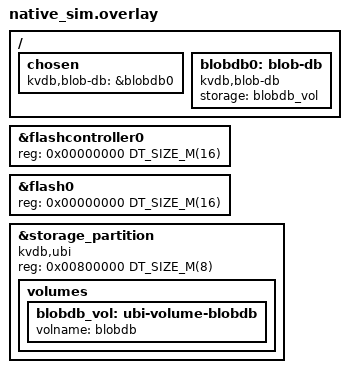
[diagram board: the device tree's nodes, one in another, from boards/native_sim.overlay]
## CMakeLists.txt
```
# Copyright (c) 2026
# SPDX-License-Identifier: Apache-2.0

cmake_minimum_required(VERSION 3.20.0)
find_package(Zephyr REQUIRED HINTS $ENV{ZEPHYR_BASE})
project(blob_db_test)

# The repository is a Zephyr module (see zephyr/module.yml): its top-level
# CMakeLists already adds lib/ and exports include/, and the blob_db library
# is built and linked automatically when CONFIG_BLOB_DB=y. Re-adding lib/
# here would create a duplicate `blob_db` target, so we only add the test.
target_sources(app PRIVATE src/main.c)
# blob_db_maintain(), its work-queue helper and the library lock.
target_sources(app PRIVATE src/maint.c)
# Power cuts during a compaction, injected under the store seam by the flash
# simulator, so they hold on every backend.
target_sources(app PRIVATE src/power_cut.c)
target_sources(app PRIVATE src/torn_append.c)
# Slots a newer build wrote, and what compaction may drop past the log's end.
target_sources(app PRIVATE src/foreign_slot.c)
# The major-5 master: header, record log, rotation, mount's doubt rules.
target_sources(app PRIVATE src/master_log.c)
# Delta slots: values against a model, and power cuts inside delta appends and
# inside compactions that rewrite chains.
target_sources_ifdef(CONFIG_BLOB_DB_DELTA app PRIVATE src/delta.c)
target_sources(app PRIVATE src/slot_index_clock.c)
# The UBI backend's own behaviour: refusing a substrate it cannot read, and the
# application hooks of <app/lib/blob_db_ubi.h>.
target_sources_ifdef(CONFIG_BLOB_DB_BACKEND_UBI app PRIVATE src/ubi.c)
```

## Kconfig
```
# Copyright (c) 2026
# SPDX-License-Identifier: Apache-2.0

mainmenu "blob_db ztest"

menu "Zephyr"
source "Kconfig.zephyr"
endmenu

# The blob_db library's Kconfig (CONFIG_BLOB_DB and friends) is contributed by
# the repository's module Kconfig entry point (zephyr/module.yml -> Kconfig ->
# rsource lib/Kconfig), so it must not be sourced again here.
```

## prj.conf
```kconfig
CONFIG_ZTEST=y
CONFIG_BLOB_DB=y
# blob_db_info_get() / blob_db_bucket_stat(), covered by the inspect cases.
CONFIG_BLOB_DB_INSPECT=y

# The corrupted-slot test bit-flips an already-written byte to simulate
# real-flash bit-rot; sim-flash refuses that by default.
CONFIG_FLASH_SIMULATOR_DOUBLE_WRITES=y

# src/power_cut.c cuts the power through the simulator's write and erase
# callbacks.
CONFIG_FLASH_SIMULATOR_CALLBACKS=y

# Compaction holds two 4 KB scratch buffers nested under a 4 KB bucket
# buffer; bump stack and ztest thread stack to fit.
CONFIG_MAIN_STACK_SIZE=32768
CONFIG_ZTEST_STACK_SIZE=32768

# Flash I/O counters, and the cause counters checked against them by
# test_iostats_causes_account_for_erases. Counting only; no behaviour changes.
CONFIG_BLOB_DB_IOSTATS=y
```

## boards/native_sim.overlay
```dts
/*
 * Match the app's overlay: 16 MB sim-flash with an 8 MB storage_partition
 * at offset 0x800000. Required so blob_db sees ≥ 4 sectors and exercises
 * the multi-bucket layout in tests.
 */

&flashcontroller0 {
	reg = <0x00000000 DT_SIZE_M(16)>;
};

&flash0 {
	reg = <0x00000000 DT_SIZE_M(16)>;
};

&storage_partition {
	/* A UBI device with one volume, which blob_db lives on. Keep
	 * "zephyr,mapped-partition": it is what makes the node a partition on
	 * native_sim.
	 */
	compatible = "kvdb,ubi", "zephyr,mapped-partition";
	reg = <0x00800000 DT_SIZE_M(8)>;

	volumes {
		blobdb_vol: ubi-volume-blobdb {
			volname = "blobdb";
		};
	};
};

/*
 * The blob_db store on the volume above. No "automount": the suite mounts,
 * formats and unmounts the store itself.
 */
/ {
	chosen {
		kvdb,blob-db = &blobdb0;
	};

	blobdb0: blob-db {
		compatible = "kvdb,blob-db";
		storage = <&blobdb_vol>;
	};
};
```

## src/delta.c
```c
/*
 * Copyright (c) 2026
 * SPDX-License-Identifier: Apache-2.0
 *
 * Delta slots (CONFIG_BLOB_DB_DELTA): an update that changes one contiguous
 * part of a value may be stored as the change against an earlier slot of the
 * same id, and every read rebuilds the value.
 *
 * blob_db_delta checks values, not mechanics: a random sequence of edits on a
 * handful of ids sharing buckets, compared after every write with a model and
 * across remounts, long enough for every bucket involved to compact. A few
 * cases then pin the mechanics the random run relies on.
 *
 * blob_db_delta_power cuts the power at every byte (and every erase) of an
 * update that appends a delta on top of a chain, and of one that compacts a
 * bucket holding chains, then checks the value the id reads back is wholly the
 * old one or wholly the new one, and that its neighbours are untouched.
 */

#include <errno.h>
#include <stdbool.h>
#include <stdint.h>
#include <string.h>

#include <zephyr/drivers/flash.h>
#include <zephyr/drivers/flash/flash_simulator.h>
#include <zephyr/storage/flash_map.h>
#include <zephyr/ztest.h>

#include <app/lib/blob_db.h>
#include <app/lib/blob_db_inspect.h>
#if defined(CONFIG_BLOB_DB_IOSTATS)
#include <app/lib/blob_db_iostats.h>
#endif

#define D_PARTITION_ID   PARTITION_ID(storage_partition)
#define D_PARTITION_SIZE DT_REG_SIZE(DT_NODELABEL(storage_partition))
#define MAXV             400   /* largest value the model builds */

/* Deterministic PRNG, so a failure replays. */
static uint32_t rng = 0x2545f491;

static uint32_t rnd(uint32_t n)
{
	rng ^= rng << 13;
	rng ^= rng >> 17;
	rng ^= rng << 5;
	return n ? rng % n : 0;
}

static void fill(uint8_t *p, size_t n)
{
	for (size_t i = 0; i < n; i++) {
		p[i] = (uint8_t)rnd(256);
	}
}

static void expect_value(uint64_t id, const uint8_t *want, size_t len, const char *when)
{
	static uint8_t got[MAXV + 8];
	size_t got_len = 0;

	zassert_ok(blob_db_get(id, got, sizeof(got), &got_len), "%s: get id %llu", when,
		   (unsigned long long)id);
	zassert_equal(got_len, len, "%s: id %llu length %zu, want %zu", when,
		      (unsigned long long)id, got_len, len);
	zassert_mem_equal(got, want, len, "%s: id %llu content", when, (unsigned long long)id);

	size_t sz = 0;

	zassert_ok(blob_db_size(id, &sz));
	zassert_equal(sz, len, "%s: size of id %llu", when, (unsigned long long)id);
}

/* One edit of the kind the recorded traffic makes, or a harder one. */
static void edit(uint8_t *v, size_t *len)
{
	size_t n = *len;
	uint32_t at = rnd((uint32_t)n + 1);
	uint32_t k;

	switch (rnd(8)) {
	case 0: /* overwrite a few bytes (counters, timestamps) */
		k = 1 + rnd(4);
		for (uint32_t i = 0; i < k && at + i < n; i++) {
			v[at + i] ^= (uint8_t)(1 + rnd(255));
		}
		break;
	case 1: /* append an entry (kvhash insert) */
		k = 1 + rnd(24);
		if (n + k <= MAXV) {
			fill(v + n, k);
			n += k;
		}
		break;
	case 2: /* insert in the middle */
		k = 1 + rnd(24);
		if (n + k <= MAXV) {
			memmove(v + at + k, v + at, n - at);
			fill(v + at, k);
			n += k;
		}
		break;
	case 3: /* remove a range */
		k = 1 + rnd(24);
		if (at + k <= n) {
			memmove(v + at, v + at + k, n - at - k);
			n -= k;
		}
		break;
	case 4: /* move a range to the end (a kvhash replace) */
		k = 1 + rnd(24);
		if (at + k <= n) {
			uint8_t tmp[24];

			memcpy(tmp, v + at, k);
			memmove(v + at, v + at + k, n - at - k);
			memcpy(v + n - k, tmp, k);
			v[n - 1] ^= 0x5a;
		}
		break;
	case 5: /* replace everything */
		n = 1 + rnd(MAXV);
		fill(v, n);
		break;
	case 6: /* truncate */
		if (n > 1) {
			n = 1 + rnd((uint32_t)n - 1);
		}
		break;
	default: /* unchanged */
		break;
	}
	*len = n;
}

/* blob_db_delta ----------------------------------------------------------- */

static void delta_before(void *fixture)
{
	ARG_UNUSED(fixture);
	blob_db_unmount();
	zassert_ok(blob_db_mount());
	zassert_ok(blob_db_format());
}

static void delta_after(void *fixture)
{
	ARG_UNUSED(fixture);
	blob_db_unmount();
}

ZTEST_SUITE(blob_db_delta, NULL, NULL, delta_before, delta_after, NULL);

#define N_IDS   12
#define N_STEPS 6000

ZTEST(blob_db_delta, test_random_edits_match_a_model)
{
	static uint8_t val[N_IDS][MAXV];
	static size_t len[N_IDS];
	uint64_t id[N_IDS];
	struct blob_db_inspect_info in;
	uint32_t gen0[N_IDS];

	zassert_ok(blob_db_inspect_info_get(&in));
	for (int i = 0; i < N_IDS; i++) {
		len[i] = 16 + rnd(200);
		fill(val[i], len[i]);
		id[i] = blob_db_alloc_id();
		zassert_ok(blob_db_update(id[i], val[i], len[i]));

		struct blob_db_inspect_bucket bs;

		zassert_ok(blob_db_inspect_bucket_get(id[i] % in.n_buckets, &bs, NULL, NULL));
		gen0[i] = bs.gen;
	}
#if defined(CONFIG_BLOB_DB_IOSTATS)
	blob_db_iostats_reset();
#endif
	for (int step = 0; step < N_STEPS; step++) {
		const int i = (int)rnd(N_IDS);

		if (rnd(64) == 0) {
			/* Deleted and re-created: a chain must not outlive its id. */
			zassert_ok(blob_db_delete(id[i]));
			zassert_equal(blob_db_get(id[i], NULL, 0, NULL), -ENOENT);
			id[i] = blob_db_alloc_id();
			len[i] = 1 + rnd(MAXV);
			fill(val[i], len[i]);
		} else {
			edit(val[i], &len[i]);
		}
		zassert_ok(blob_db_update(id[i], val[i], len[i]), "step %d", step);
		expect_value(id[i], val[i], len[i], "after update");

		if (step % 1000 == 999) {
			blob_db_unmount();
			zassert_ok(blob_db_mount());
			for (int j = 0; j < N_IDS; j++) {
				expect_value(id[j], val[j], len[j], "after remount");
			}
		}
	}

	/* The run is only a test of deltas and of their compaction if both
	 * happened. */
	int compacted = 0;

	for (int i = 0; i < N_IDS; i++) {
		struct blob_db_inspect_bucket bs;

		zassert_ok(blob_db_inspect_bucket_get(id[i] % in.n_buckets, &bs, NULL, NULL));
		compacted += bs.gen > gen0[i] + 1;
	}
	zassert_true(compacted > 0, "no bucket compacted during the run");
#if defined(CONFIG_BLOB_DB_IOSTATS)
	struct blob_db_iostats io;

	blob_db_iostats_get(&io);
	zassert_true(io.delta_slots > N_STEPS / 4, "only %u delta slots in %d updates",
		     io.delta_slots, N_STEPS);
	zassert_true(io.compactions > 0);
#endif
}

ZTEST(blob_db_delta, test_small_change_is_written_as_a_delta)
{
#if !defined(CONFIG_BLOB_DB_IOSTATS)
	ztest_test_skip();
#else
	uint8_t v[160];
	struct blob_db_iostats a, b;

	fill(v, sizeof(v));
	const uint64_t id = blob_db_alloc_id();

	zassert_ok(blob_db_update(id, v, sizeof(v)));
	blob_db_iostats_get(&a);
	v[80] ^= 1;
	zassert_ok(blob_db_update(id, v, sizeof(v)));
	blob_db_iostats_get(&b);
	zassert_equal(b.delta_slots - a.delta_slots, 1, "a one-byte change was not a delta");
	zassert_true(b.bytes_written - a.bytes_written < 40,
		     "a one-byte delta cost %llu bytes",
		     (unsigned long long)(b.bytes_written - a.bytes_written));
	expect_value(id, v, sizeof(v), "one-byte delta");
#endif
}

ZTEST(blob_db_delta, test_compaction_writes_chains_out_in_full)
{
	struct blob_db_inspect_info in;
	struct blob_db_inspect_bucket bs;
	uint8_t v[120];
	uint8_t w[120];

	zassert_ok(blob_db_inspect_info_get(&in));
	fill(v, sizeof(v));
	fill(w, sizeof(w));

	/* Two ids in one bucket, both chained, then fill the bucket until it
	 * compacts. */
	const uint64_t a = blob_db_alloc_id();
	uint64_t b;

	do {
		b = blob_db_alloc_id();
	} while (b % in.n_buckets != a % in.n_buckets);

	zassert_ok(blob_db_update(a, v, sizeof(v)));
	zassert_ok(blob_db_update(b, w, sizeof(w)));
	zassert_ok(blob_db_inspect_bucket_get(a % in.n_buckets, &bs, NULL, NULL));

	const uint32_t gen = bs.gen;

	for (int n = 0; n < 2000; n++) {
		v[n % sizeof(v)]++;
		zassert_ok(blob_db_update(a, v, sizeof(v)));
		if (n % 3 == 0) {
			w[(n * 7) % sizeof(w)]++;
			zassert_ok(blob_db_update(b, w, sizeof(w)));
		}
		zassert_ok(blob_db_inspect_bucket_get(a % in.n_buckets, &bs, NULL, NULL));
		if (bs.gen > gen) {
			break;
		}
	}
	zassert_true(bs.gen > gen, "the bucket never compacted");
	zassert_equal(bs.objects, 2);
	expect_value(a, v, sizeof(v), "after compaction");
	expect_value(b, w, sizeof(w), "after compaction");
	blob_db_unmount();
	zassert_ok(blob_db_mount());
	expect_value(a, v, sizeof(v), "after compaction and remount");
	expect_value(b, w, sizeof(w), "after compaction and remount");
}

ZTEST(blob_db_delta, test_delete_over_a_chain)
{
	uint8_t v[100];

	fill(v, sizeof(v));
	const uint64_t id = blob_db_alloc_id();

	zassert_ok(blob_db_update(id, v, sizeof(v)));
	for (int i = 0; i < 5; i++) {
		v[i * 3] ^= 0xff;
		zassert_ok(blob_db_update(id, v, sizeof(v)));
	}
	zassert_ok(blob_db_delete(id));
	zassert_equal(blob_db_get(id, NULL, 0, NULL), -ENOENT);
	zassert_false(blob_db_exists(id));
	blob_db_unmount();
	zassert_ok(blob_db_mount());
	zassert_equal(blob_db_get(id, NULL, 0, NULL), -ENOENT);
}

ZTEST(blob_db_delta, test_short_buffer_reports_the_rebuilt_length)
{
	uint8_t v[200];
	uint8_t small[16];
	size_t got = 0;

	fill(v, sizeof(v));
	const uint64_t id = blob_db_alloc_id();

	zassert_ok(blob_db_update(id, v, 150));
	zassert_ok(blob_db_update(id, v, 200));   /* grown by a delta */
	zassert_equal(blob_db_get(id, small, sizeof(small), &got), -ENOMEM);
	zassert_ok(blob_db_size(id, &got));
	zassert_equal(got, 200);

	uint8_t part[50];

	zassert_ok(blob_db_read(id, 120, part, sizeof(part), &got));
	zassert_equal(got, sizeof(part));
	zassert_mem_equal(part, v + 120, sizeof(part));
}

static struct {
	uint64_t id;
	const uint8_t *want;
	size_t len;
	int seen, matched;
} it;

static int it_cb(uint64_t id, const void *p, size_t len, void *user)
{
	ARG_UNUSED(user);
	if (id == it.id) {
		it.seen++;
		it.matched += (len == it.len && memcmp(p, it.want, len) == 0);
	}
	return 0;
}

ZTEST(blob_db_delta, test_iterate_and_count_see_rebuilt_values)
{
	/* count() and iterate() walk resident sectors; a delta there must be
	 * reported as the value it describes, not as its own payload. */
	uint8_t v[90];

	fill(v, sizeof(v));
	const uint64_t id = blob_db_alloc_id();
	const size_t before = blob_db_count();

	zassert_ok(blob_db_update(id, v, sizeof(v)));
	for (int i = 0; i < 3; i++) {
		v[10 + i] ^= 1;
		zassert_ok(blob_db_update(id, v, sizeof(v)));
	}
	zassert_equal(blob_db_count(), before + 1);
	it.id = id;
	it.want = v;
	it.len = sizeof(v);
	it.seen = it.matched = 0;
	zassert_ok(blob_db_iterate(it_cb, NULL));
	zassert_equal(it.seen, 1);
	zassert_equal(it.matched, 1, "iterate handed out the delta, not the value");
}

/* blob_db_delta_power ----------------------------------------------------- */

static struct {
	bool cut;
	bool armed;
	uint32_t budget;
	bool erase_armed;
	uint32_t erase_budget;
	bool tear_head;
	uint32_t bytes;
	uint32_t erases;
	off_t first_off[4];
} pw;

static const struct device *sim;
static uint8_t *sim_part;
static size_t erase_unit;
static uint8_t erase_value;
static uint8_t snap[D_PARTITION_SIZE];

static int pw_write_byte(const struct device *dev, off_t off, uint8_t data)
{
	ARG_UNUSED(dev);
	if (pw.cut) {
		return -EIO;
	}
	if (pw.armed) {
		if (pw.budget == 0) {
			pw.cut = true;
			return -EIO;
		}
		pw.budget--;
	}
	if (pw.bytes < 4) {
		pw.first_off[pw.bytes] = off;
	}
	pw.bytes++;
	return data;
}

static int pw_erase_unit(const struct device *dev, off_t unit_off)
{
	size_t size;
	uint8_t *mem = flash_simulator_get_memory(dev, &size);

	if (pw.cut) {
		return -EIO;
	}
	if (pw.erase_armed) {
		if (pw.erase_budget == 0) {
			memset(&mem[unit_off + (pw.tear_head ? 0 : erase_unit / 2)], erase_value,
			       erase_unit / 2);
			pw.cut = true;
			return -EIO;
		}
		pw.erase_budget--;
	}
	memset(&mem[unit_off], erase_value, erase_unit);
	pw.erases++;
	return 0;
}

static const struct flash_simulator_cb pw_cb = {
	.write_byte = pw_write_byte,
	.erase_unit = pw_erase_unit,
};

static void *power_setup(void)
{
	const struct flash_area *fa;
	struct flash_pages_info page;
	size_t size;

	zassert_ok(flash_area_open(D_PARTITION_ID, &fa));
	sim = fa->fa_dev;
	zassert_ok(flash_get_page_info_by_offs(sim, fa->fa_off, &page));
	erase_unit = page.size;
	erase_value = flash_get_parameters(sim)->erase_value;
	sim_part = (uint8_t *)flash_simulator_get_memory(sim, &size) + fa->fa_off;
	flash_area_close(fa);
	memset(&pw, 0, sizeof(pw));
	flash_simulator_set_callbacks(sim, &pw_cb);
	return NULL;
}

static void power_teardown(void *fixture)
{
	ARG_UNUSED(fixture);
	flash_simulator_set_callbacks(sim, NULL);
}

static void power_before(void *fixture)
{
	ARG_UNUSED(fixture);
	memset(&pw, 0, sizeof(pw));
	blob_db_unmount();
	zassert_ok(blob_db_mount());
	zassert_ok(blob_db_format());
}

ZTEST_SUITE(blob_db_delta_power, NULL, power_setup, power_before, NULL, power_teardown);

#define N_SIB 4
#define VLEN  96

static struct {
	uint64_t target;
	uint64_t sib[N_SIB];
	uint8_t sib_val[N_SIB][VLEN];
	uint8_t old_val[VLEN];
	uint8_t new_val[VLEN];
} ps;

static bool value_is(uint64_t id, const uint8_t *want)
{
	uint8_t got[VLEN + 8];
	size_t len = 0;

	return blob_db_get(id, got, sizeof(got), &len) == 0 && len == VLEN &&
	       memcmp(got, want, VLEN) == 0;
}

/* Build a target and siblings in one bucket, each with a delta chain. With
 * @p near_full, keep updating the siblings until the target's next update
 * cannot fit without a compaction. */
static void scenario(bool near_full)
{
	struct blob_db_inspect_info in;
	struct blob_db_inspect_bucket bs;

	zassert_ok(blob_db_inspect_info_get(&in));
	fill(ps.old_val, VLEN);
	ps.target = blob_db_alloc_id();
	zassert_ok(blob_db_update(ps.target, ps.old_val, VLEN));
	for (int i = 0; i < N_SIB; i++) {
		do {
			ps.sib[i] = blob_db_alloc_id();
		} while (ps.sib[i] % in.n_buckets != ps.target % in.n_buckets);
		fill(ps.sib_val[i], VLEN);
		zassert_ok(blob_db_update(ps.sib[i], ps.sib_val[i], VLEN));
	}
	/* Two small, adjacent edits each: a chain of two deltas on every id,
	 * short enough that one more is still a delta under either policy. */
	for (int k = 0; k < 2; k++) {
		ps.old_val[40 + k] ^= 0x33;
		zassert_ok(blob_db_update(ps.target, ps.old_val, VLEN));
		for (int i = 0; i < N_SIB; i++) {
			ps.sib_val[i][30 + k] ^= 0x44;
			zassert_ok(blob_db_update(ps.sib[i], ps.sib_val[i], VLEN));
		}
	}
	if (near_full) {
		/* Small updates until the free tail could not take one more
		 * full slot of the target. */
		for (int n = 0; n < 4000; n++) {
			zassert_ok(blob_db_inspect_bucket_get(ps.target % in.n_buckets, &bs, NULL,
							      NULL));
			if (bs.free_bytes < in.slot_overhead + VLEN) {
				break;   /* a full slot of the target no longer fits */
			}
			const int i = n % N_SIB;

			ps.sib_val[i][n % VLEN]++;
			zassert_ok(blob_db_update(ps.sib[i], ps.sib_val[i], VLEN));
		}
	}
	memcpy(ps.new_val, ps.old_val, VLEN);
	if (near_full) {
		fill(ps.new_val, VLEN);         /* a full slot: forces the compaction */
	} else {
		ps.new_val[42] ^= 0x01;   /* a delta on top of the chain */
	}
}

static void check_after_cut(int rc, uint32_t cut, const char *what)
{
	pw.armed = false;
	pw.erase_armed = false;
	pw.cut = false;
	blob_db_unmount();
	zassert_ok(blob_db_mount(), "%s cut %u: mount", what, cut);

	const bool is_old = value_is(ps.target, ps.old_val);
	const bool is_new = value_is(ps.target, ps.new_val);

	zassert_true(is_old || is_new, "%s cut %u: target is neither old nor new", what, cut);
	if (rc == 0) {
		zassert_true(is_new, "%s cut %u: update reported success but value is old", what,
			     cut);
	}
	for (int i = 0; i < N_SIB; i++) {
		zassert_true(value_is(ps.sib[i], ps.sib_val[i]), "%s cut %u: sibling %d damaged",
			     what, cut, i);
	}

	/* The recovered store takes a write that survives a further remount. */
	uint8_t v[VLEN];

	memcpy(v, ps.sib_val[0], VLEN);
	v[0] ^= 0x80;
	zassert_ok(blob_db_update(ps.sib[0], v, VLEN), "%s cut %u: write after recovery", what,
		   cut);
	{
		uint8_t g[VLEN + 8];
		size_t gl = 0;
		int grc = blob_db_get(ps.sib[0], g, sizeof(g), &gl);

		if (grc != 0 || gl != VLEN || memcmp(g, v, VLEN) != 0) {
			TC_PRINT("%s cut %u: before remount get rc=%d len=%zu\n", what, cut, grc, gl);
		}
	}
	blob_db_unmount();
	zassert_ok(blob_db_mount());
	if (!value_is(ps.sib[0], v)) {
		uint8_t g[VLEN + 8];
		size_t gl = 0;
		int grc = blob_db_get(ps.sib[0], g, sizeof(g), &gl);
		int first = -1;

		for (int i = 0; i < VLEN && grc == 0; i++) {
			if (g[i] != v[i]) {
				first = i;
				break;
			}
		}
		TC_PRINT("%s cut %u: after remount get rc=%d len=%zu first diff %d (old? %d)\n",
			 what, cut, grc, gl, first,
			 grc == 0 && memcmp(g, ps.sib_val[0], VLEN) == 0);
	}
	zassert_true(value_is(ps.sib[0], v), "%s cut %u: write after recovery lost", what, cut);
}

static void sweep(const char *what)
{
	/* Reference run: how many bytes and erases the update makes. */
	blob_db_unmount();
	memcpy(snap, sim_part, sizeof(snap));
	zassert_ok(blob_db_mount());
	pw.bytes = 0;
	pw.erases = 0;
	zassert_ok(blob_db_update(ps.target, ps.new_val, VLEN));
	zassert_true(value_is(ps.target, ps.new_val));

	const uint32_t bytes = pw.bytes;
	const uint32_t erases = pw.erases;
	struct blob_db_inspect_info in;

	zassert_ok(blob_db_inspect_info_get(&in));
	if (strcmp(what, "delta append") == 0) {
		zassert_true(bytes < in.slot_overhead + VLEN,
			     "the reference update wrote %u bytes: not a delta", bytes);
	}

	TC_PRINT("%s: first writes at 0x%lx 0x%lx 0x%lx 0x%lx (partition at 0x%lx)\n", what,
		 (long)pw.first_off[0], (long)pw.first_off[1], (long)pw.first_off[2],
		 (long)pw.first_off[3], (long)(sim_part - (uint8_t *)flash_simulator_get_memory(sim, &(size_t){0})));

	zassert_true(bytes > 0, "%s: the update wrote nothing", what);

	for (uint32_t cut = 0; cut < bytes;
	     cut += (cut < 96 || bytes - cut < 96) ? 1 : 13) {
		blob_db_unmount();
		memcpy(sim_part, snap, sizeof(snap));
		zassert_ok(blob_db_mount());
		pw.cut = false;
		pw.budget = cut;
		pw.armed = true;

		const int rc = blob_db_update(ps.target, ps.new_val, VLEN);

		check_after_cut(rc, cut, what);
	}
	for (uint32_t e = 0; e < erases; e++) {
		for (int half = 0; half < 2; half++) {
			blob_db_unmount();
			memcpy(sim_part, snap, sizeof(snap));
			zassert_ok(blob_db_mount());
			pw.cut = false;
			pw.erase_budget = e;
			pw.erase_armed = true;
			pw.tear_head = half == 0;

			const int rc = blob_db_update(ps.target, ps.new_val, VLEN);

			check_after_cut(rc, 100000 + e * 2 + (uint32_t)half, what);
		}
	}
	TC_PRINT("%s: %u write bytes, %u erases swept\n", what, bytes, erases);
}

ZTEST(blob_db_delta_power, test_cut_during_a_delta_append)
{
	scenario(false);
	sweep("delta append");
}

ZTEST(blob_db_delta_power, test_cut_during_a_compaction_of_chains)
{
	scenario(true);
	sweep("compaction of chains");
}
```

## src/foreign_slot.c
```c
/*
 * Copyright (c) 2026
 * SPDX-License-Identifier: Apache-2.0
 *
 * Slots this build cannot read, and what compaction may drop
 * (doc/proposals/2026-10-28-master-log.md D13, implementation plan PR 3).
 *
 * A foreign slot is whole (sealed, sized, CRC intact) but carries a slot flag
 * this build does not know: a newer build wrote it. It is data, not a torn
 * tail, so its bucket answers no read (-EIO) and takes no write (-ENOTSUP),
 * and compaction never drops it. Separately, compaction drops what its walk
 * cannot reach only when that is the remains of one torn append, at most one
 * slot span past where the log ends.
 *
 * The cases forge flash at blob_db's own offsets, so they run on the
 * flash_area backend and skip on UBI (see SKIP_UNLESS_RAW_PARTITION in
 * main.c).
 */

#include <errno.h>
#include <stdbool.h>
#include <stdint.h>
#include <string.h>

#include <zephyr/storage/flash_map.h>
#include <zephyr/sys/crc.h>
#include <zephyr/ztest.h>

#include <app/lib/blob_db.h>

#define FS_PARTITION_ID  PARTITION_ID(storage_partition)
#define FS_SECTOR_SZ     4096   /* native_sim overlay: 4 KB sectors */
#define FS_N_BUCKETS     2045   /* 2048 sectors - 2 masters - scratch */
#define FS_SEALED        0x01
/* A slot flag no build assigns yet: bit 6 is free in the registry of the
 * master-log proposal (§4.2), so every build here reads it as unknown. */
#define FS_FLAG_UNKNOWN  0x40
/* Flags whose combination the format leaves undefined (DELTA with any of
 * TOMBSTONE, INDEXED, SEGMENT): foreign to every build, delta or not. */
#define FS_TOMBSTONE     0x02
#define FS_INDEXED       0x04
#define FS_SEGMENT       0x08
#define FS_DELTA         0x20

#define FS_SKIP_UNLESS_RAW_PARTITION() \
	Z_TEST_SKIP_IFNDEF(CONFIG_BLOB_DB_BACKEND_FLASH_AREA)

struct __packed fs_slot_head {
	uint8_t  flags;
	uint8_t  reserved;
	uint16_t val_len;
	uint64_t id;
};

static uint8_t fs_before[FS_SECTOR_SZ];
static uint8_t fs_after[FS_SECTOR_SZ];

static off_t fs_bucket_off(uint16_t bid)
{
	return (off_t)(3 + bid) * FS_SECTOR_SZ;
}

static size_t fs_align(void)
{
	const struct flash_area *fa;

	zassert_ok(flash_area_open(FS_PARTITION_ID, &fa));

	const size_t a = flash_area_align(fa);

	flash_area_close(fa);
	return a ? a : 1;
}

static size_t fs_slot_size(uint16_t val_len)
{
	const size_t a = fs_align();

	return (14 + val_len + a - 1) & ~(a - 1);
}

static void fs_read_bucket(uint16_t bid, uint8_t *buf)
{
	const struct flash_area *fa;

	zassert_ok(flash_area_open(FS_PARTITION_ID, &fa));
	zassert_ok(flash_area_read(fa, fs_bucket_off(bid), buf, FS_SECTOR_SZ));
	flash_area_close(fa);
}

static void fs_write(off_t off, const void *buf, size_t len)
{
	const struct flash_area *fa;

	zassert_ok(flash_area_open(FS_PARTITION_ID, &fa));
	zassert_ok(flash_area_write(fa, off, buf, len));
	flash_area_close(fa);
}

/* Where the next slot of bucket @p bid would land: the first erased header. */
static off_t fs_cursor(uint16_t bid)
{
	off_t cursor = 16;

	fs_read_bucket(bid, fs_before);
	for (;;) {
		const struct fs_slot_head *h =
			(const struct fs_slot_head *)(fs_before + cursor);

		if (cursor + 14 > FS_SECTOR_SZ || h->flags == 0xff) {
			return cursor;
		}
		cursor += (off_t)fs_slot_size(h->val_len);
	}
}

/* Append, by hand, the slot a newer build would write: whole and intact, with
 * a flag this build does not know. */
static void forge_slot(uint16_t bid, uint64_t id, uint8_t flags, const char *val)
{
	static uint8_t slot[64];
	const uint16_t len = (uint16_t)strlen(val);
	const size_t ssz = fs_slot_size(len);
	struct fs_slot_head h = {
		.flags = flags,
		.val_len = len,
		.id = id,
	};

	zassert_true(ssz <= sizeof(slot));
	memset(slot, 0xff, sizeof(slot));
	memcpy(slot, &h, sizeof(h));
	memcpy(slot + sizeof(h), val, len);

	uint16_t crc = crc16_ccitt(0xffff, (const uint8_t *)&h, 4);

	crc = crc16_ccitt(crc, (const uint8_t *)&h.id, sizeof(h.id));
	crc = crc16_ccitt(crc, (const uint8_t *)val, len);
	memcpy(slot + sizeof(h) + len, &crc, sizeof(crc));

	fs_write(fs_bucket_off(bid) + fs_cursor(bid), slot, ssz);
}

static void forge_foreign_slot(uint16_t bid, uint64_t id, const char *val)
{
	forge_slot(bid, id, FS_SEALED | FS_FLAG_UNKNOWN, val);
}

/* What a power cut leaves when it tears a slot inside its header: a sealed
 * flags byte and a length no slot can have, so the walk cannot size it. */
static off_t forge_torn_header(uint16_t bid)
{
	const off_t at = fs_cursor(bid);
	const uint8_t head[4] = { FS_SEALED, 0x00, 0xff, 0xff };

	fs_write(fs_bucket_off(bid) + at, head, sizeof(head));
	return at;
}

static uint64_t fs_put(const char *val)
{
	const uint64_t id = blob_db_alloc_id();

	zassert_not_equal(id, 0);
	zassert_ok(blob_db_update(id, val, strlen(val)));
	return id;
}

static void fs_assert_blob(uint64_t id, const char *val)
{
	uint8_t buf[16];
	size_t got;

	zassert_ok(blob_db_get(id, buf, sizeof(buf), &got));
	zassert_equal(got, strlen(val));
	zassert_mem_equal(buf, val, got);
}

static int fs_count_cb(uint64_t id, const void *p, size_t len, void *user)
{
	ARG_UNUSED(id);
	ARG_UNUSED(p);
	ARG_UNUSED(len);
	(*(int *)user)++;
	return 0;
}

static void fs_before_each(void *fixture)
{
	ARG_UNUSED(fixture);
	blob_db_unmount();
	zassert_ok(blob_db_mount(), "mount failed in setup");
	zassert_ok(blob_db_format(), "format failed in setup");
}

static void fs_after_each(void *fixture)
{
	ARG_UNUSED(fixture);
	blob_db_unmount();
}

ZTEST_SUITE(blob_db_foreign, NULL, NULL, fs_before_each, fs_after_each, NULL);

/* A newer build appended a slot for an id this build holds an older version
 * of. Answering with the older version would be stale data; dropping the
 * newer one at the next compaction would lose it. Before, the walk took the
 * slot for a torn tail and did both. */
ZTEST(blob_db_foreign, test_foreign_slot_closes_its_bucket)
{
	FS_SKIP_UNLESS_RAW_PARTITION();

	const uint64_t id = fs_put("OLD");
	const uint64_t elsewhere = fs_put("ELSE");
	const uint16_t bid = (uint16_t)(id % FS_N_BUCKETS);
	uint8_t buf[16];
	size_t got;

	zassert_not_equal((uint16_t)(elsewhere % FS_N_BUCKETS), bid);
	zassert_ok(blob_db_unmount());
	forge_foreign_slot(bid, id, "NEWER");
	fs_read_bucket(bid, fs_before);

	for (int pass = 0; pass < 2; pass++) {
		zassert_ok(blob_db_mount());

		zassert_equal(blob_db_get(id, buf, sizeof(buf), &got), -EIO,
			      "pass %d: served a version a newer slot replaces",
			      pass);
		zassert_equal(blob_db_size(id, &got), -EIO);
		zassert_equal(blob_db_read(id, 0, buf, sizeof(buf), &got), -EIO);
		zassert_false(blob_db_exists(id));

		zassert_equal(blob_db_update(id, "X", 1), -ENOTSUP,
			      "pass %d: wrote into a bucket it cannot read", pass);
		zassert_equal(blob_db_write(id, 0, "X", 1), -ENOTSUP);
		zassert_equal(blob_db_delete(id), -ENOTSUP);

		int seen = 0;

		zassert_equal(blob_db_iterate(fs_count_cb, &seen), -EIO);

		/* Every other bucket works as before. */
		fs_assert_blob(elsewhere, pass == 0 ? "ELSE" : "MORE");
		zassert_ok(blob_db_update(elsewhere, "MORE", 4));
		fs_assert_blob(elsewhere, "MORE");

		zassert_ok(blob_db_unmount());
		fs_read_bucket(bid, fs_after);
		zassert_mem_equal(fs_after, fs_before, FS_SECTOR_SZ,
				  "pass %d: the bucket was written", pass);
	}
}

/* DELTA combined with TOMBSTONE, INDEXED or SEGMENT means nothing yet. A
 * whole slot carrying such a combination is foreign, as an unknown bit is:
 * not served, not written over, not dropped. */
ZTEST(blob_db_foreign, test_undefined_delta_combinations_are_foreign)
{
	FS_SKIP_UNLESS_RAW_PARTITION();

	static const uint8_t combos[] = {
		FS_SEALED | FS_DELTA | FS_TOMBSTONE,
		FS_SEALED | FS_DELTA | FS_INDEXED,
		FS_SEALED | FS_DELTA | FS_SEGMENT,
	};

	for (size_t k = 0; k < ARRAY_SIZE(combos); k++) {
		const uint64_t id = fs_put("OLD");
		const uint16_t bid = (uint16_t)(id % FS_N_BUCKETS);
		uint8_t buf[16];
		size_t got;

		zassert_ok(blob_db_unmount());
		forge_slot(bid, id, combos[k], "0123456789");
		fs_read_bucket(bid, fs_before);
		zassert_ok(blob_db_mount());

		zassert_equal(blob_db_get(id, buf, sizeof(buf), &got), -EIO,
			      "flags 0x%02x: served the older value", combos[k]);
		zassert_equal(blob_db_update(id, "X", 1), -ENOTSUP,
			      "flags 0x%02x: wrote into the bucket", combos[k]);

		zassert_ok(blob_db_unmount());
		fs_read_bucket(bid, fs_after);
		zassert_mem_equal(fs_after, fs_before, FS_SECTOR_SZ,
				  "flags 0x%02x: the bucket was written", combos[k]);
		zassert_ok(blob_db_mount());
	}
}

/* The root's bucket holds a foreign slot. Binding an empty root, as mount does
 * when it finds none, would reformat the bucket and erase the slot, so mount
 * refuses instead and writes nothing there. */
ZTEST(blob_db_foreign, test_foreign_slot_in_the_root_bucket_refuses_mount)
{
	FS_SKIP_UNLESS_RAW_PARTITION();

	const uint16_t root_bid = (uint16_t)(BLOB_DB_ROOT_ID % FS_N_BUCKETS);

	zassert_ok(blob_db_unmount());
	forge_foreign_slot(root_bid, BLOB_DB_ROOT_ID, "ROOT2");
	fs_read_bucket(root_bid, fs_before);

	zassert_equal(blob_db_mount(), -ENOTSUP);
	fs_read_bucket(root_bid, fs_after);
	zassert_mem_equal(fs_after, fs_before, FS_SECTOR_SZ,
			  "the root bucket was written");

	/* Leave a store the next setup can mount: blank masters format. */
	const struct flash_area *fa;

	zassert_ok(flash_area_open(FS_PARTITION_ID, &fa));
	zassert_ok(flash_area_erase(fa, 0, 3 * FS_SECTOR_SZ));
	flash_area_close(fa);
}

/* A torn header with stray bits programmed further into the slot it began,
 * out of order, as a page program cut midway leaves them. That is one torn
 * append, so compaction still drops it, and the write that needed the
 * compaction lands. */
ZTEST(blob_db_foreign, test_torn_append_with_stray_bits_still_compacts)
{
	FS_SKIP_UNLESS_RAW_PARTITION();

	const uint64_t id = fs_put("KEEP");
	const uint16_t bid = (uint16_t)(id % FS_N_BUCKETS);
	const uint8_t stray = 0x00;

	zassert_ok(blob_db_unmount());

	const off_t at = forge_torn_header(bid);

	fs_write(fs_bucket_off(bid) + at + 100, &stray, 1);

	zassert_ok(blob_db_mount());
	fs_assert_blob(id, "KEEP");
	zassert_ok(blob_db_update(id, "NEW", 3),
		   "a torn append's remains blocked the compaction");
	fs_assert_blob(id, "NEW");
}

/* Programmed bytes further past the end of the log than one append can
 * reach: data the walk cannot read, from a build with a larger payload cap or
 * a stride the walk lost. Compaction would drop it, so it refuses, and the
 * bucket stays as it is. Before, compaction dropped it. */
ZTEST(blob_db_foreign, test_bytes_past_one_slot_span_block_compaction)
{
	FS_SKIP_UNLESS_RAW_PARTITION();

	const uint64_t id = fs_put("KEEP");
	const uint16_t bid = (uint16_t)(id % FS_N_BUCKETS);
	const uint8_t data = 0x00;

	zassert_ok(blob_db_unmount());

	const off_t at = forge_torn_header(bid);
	const off_t beyond = at + (off_t)fs_slot_size(CONFIG_BLOB_DB_MAX_PAYLOAD_LEN) + 8;

	if (beyond >= FS_SECTOR_SZ) {
		ztest_test_skip();   /* the cap leaves no room past one span */
	}
	fs_write(fs_bucket_off(bid) + beyond, &data, 1);
	fs_read_bucket(bid, fs_before);

	zassert_ok(blob_db_mount());
	zassert_equal(blob_db_update(id, "NEW", 3), -EIO,
		      "compaction dropped bytes past one slot span");
	fs_assert_blob(id, "KEEP");
	zassert_ok(blob_db_unmount());

	fs_read_bucket(bid, fs_after);
	zassert_mem_equal(fs_after, fs_before, FS_SECTOR_SZ,
			  "the bucket was written");
}
```

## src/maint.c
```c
/*
 * Copyright (c) 2026
 * SPDX-License-Identifier: Apache-2.0
 *
 * blob_db_maintain(), the background helper that runs it on a work queue
 * (CONFIG_BLOB_DB_MAINT_WORK), and the library lock that makes both safe next
 * to another thread's blob_db calls.
 *
 * What a step does is the backend's business, so the cases here hold on both:
 * the work drains, draining changes nothing a reader sees, and calls from two
 * threads interleave without losing a write. The backend-specific halves are
 * the flash_area case below (fresh buckets get formatted) and the UBI cases
 * in src/ubi.c (blocks get reclaimed, and no blob_db call erases meanwhile).
 */

#include <errno.h>
#include <stdint.h>
#include <string.h>

#include <zephyr/kernel.h>
#include <zephyr/ztest.h>

#include <app/lib/blob_db.h>
#include <app/lib/blob_db_inspect.h>

/* UBI without atomic replace erases every block inline, so it never defers
 * any: the cases that need work to exist skip there. */
#define SKIP_UNLESS_WORK_IS_DEFERRED()					\
	do {								\
		if (IS_ENABLED(CONFIG_BLOB_DB_BACKEND_UBI) &&		\
		    !IS_ENABLED(CONFIG_BLOB_DB_UBI_ATOMIC_REPLACE)) {	\
			ztest_test_skip();				\
		}							\
	} while (0)

/* More steps than any store in this suite has blocks: the 8 MB partition of
 * 4 KB sectors has about 2 000. */
#define DRAIN_LIMIT 8192

static void maint_before(void *fixture)
{
	ARG_UNUSED(fixture);
	blob_db_unmount();
	zassert_ok(blob_db_mount(), "mount failed in setup");
	zassert_ok(blob_db_format(), "format failed in setup");
}

static void maint_after(void *fixture)
{
	ARG_UNUSED(fixture);
#if defined(CONFIG_BLOB_DB_MAINT_WORK)
	blob_db_maint_stop();
#endif
	blob_db_unmount();
}

ZTEST_SUITE(blob_db_maint, NULL, NULL, maint_before, maint_after, NULL);

/* Run one step at a time until nothing is left; return the steps taken. */
static uint32_t drain(void)
{
	uint32_t total = 0;

	for (int i = 0; i < DRAIN_LIMIT; i++) {
		struct blob_db_maint_result res;

		zassert_ok(blob_db_maintain(1, &res));
		zassert_true(res.performed <= 1, "a step budget of 1 ran %u",
			     res.performed);
		total += res.performed;
		if (!res.more) {
			return total;
		}
	}
	zassert_unreachable("maintenance did not drain in %d steps", DRAIN_LIMIT);
	return total;
}

/* Rebind one id until its bucket has compacted a few times. On UBI each
 * compaction leaves a block waiting for reclaim; on flash_area it leaves
 * fresh buckets fresh. Either way there is work afterwards. */
static uint64_t make_work(void)
{
	static uint8_t payload[CONFIG_BLOB_DB_MAX_PAYLOAD_LEN];
	const uint64_t id = blob_db_alloc_id();

	for (int i = 0; i < 64; i++) {
		memset(payload, i, sizeof(payload));
		zassert_ok(blob_db_update(id, payload, sizeof(payload)));
	}
	return id;
}

ZTEST(blob_db_maint, test_not_mounted)
{
	struct blob_db_maint_result res = { .performed = 7, .more = true };

	blob_db_unmount();
	zassert_equal(blob_db_maintain(1, &res), -ENODEV);
	zassert_equal(res.performed, 0);
	zassert_false(res.more);
}

/* Budget 0 reports and runs nothing: a second report says the same. */
ZTEST(blob_db_maint, test_zero_budget_only_reports)
{
	SKIP_UNLESS_WORK_IS_DEFERRED();

	struct blob_db_maint_result first;
	struct blob_db_maint_result again;

	(void)make_work();
	zassert_ok(blob_db_maintain(0, &first));
	zassert_equal(first.performed, 0);
	zassert_true(first.more, "make_work() must leave work to report");
	zassert_ok(blob_db_maintain(0, &again));
	zassert_equal(again.performed, 0);
	zassert_true(again.more);
	zassert_ok(blob_db_maintain(0, NULL));
}

/* Once drained there is nothing left, and a later call does nothing. */
ZTEST(blob_db_maint, test_drains_and_stays_drained)
{
	SKIP_UNLESS_WORK_IS_DEFERRED();

	struct blob_db_maint_result res;

	(void)make_work();
	zassert_true(drain() > 0, "make_work() must leave work to drain");
	zassert_ok(blob_db_maintain(8, &res));
	zassert_equal(res.performed, 0);
	zassert_false(res.more);
}

/* Draining changes nothing a reader sees, the root included, and the store
 * keeps working afterwards — across a remount too. */
ZTEST(blob_db_maint, test_drain_preserves_contents)
{
	static const uint8_t root[] = "root survives";
	static const uint8_t small[] = "small";
	uint8_t big[CONFIG_BLOB_DB_MAX_PAYLOAD_LEN];
	uint8_t buf[CONFIG_BLOB_DB_MAX_PAYLOAD_LEN];
	size_t got;

	zassert_ok(blob_db_update(BLOB_DB_ROOT_ID, root, sizeof(root)));
	const uint64_t a = make_work();
	const uint64_t b = blob_db_alloc_id();

	zassert_ok(blob_db_update(b, small, sizeof(small)));
	(void)drain();

	memset(big, 63, sizeof(big));   /* make_work()'s last payload */
	zassert_ok(blob_db_get(a, buf, sizeof(buf), &got));
	zassert_equal(got, sizeof(big));
	zassert_mem_equal(buf, big, sizeof(big));
	zassert_ok(blob_db_get(BLOB_DB_ROOT_ID, buf, sizeof(buf), &got));
	zassert_mem_equal(buf, root, sizeof(root));

	const uint64_t c = blob_db_alloc_id();

	zassert_ok(blob_db_update(c, small, sizeof(small)));

	zassert_ok(blob_db_unmount());
	zassert_ok(blob_db_mount());
	zassert_ok(blob_db_get(b, buf, sizeof(buf), &got));
	zassert_mem_equal(buf, small, sizeof(small));
	zassert_ok(blob_db_get(c, buf, sizeof(buf), &got));
	zassert_mem_equal(buf, small, sizeof(small));
	zassert_equal(blob_db_count(), 4);
}

/* flash_area: a step formats one never-written bucket, until every bucket
 * has a header; the steps taken are exactly the fresh buckets. */
ZTEST(blob_db_maint, test_flash_area_formats_fresh_buckets)
{
	Z_TEST_SKIP_IFNDEF(CONFIG_BLOB_DB_BACKEND_FLASH_AREA);

	struct blob_db_inspect_info info;
	struct blob_db_inspect_bucket bucket;
	uint32_t fresh = 0;

	zassert_ok(blob_db_inspect_info_get(&info));
	for (uint16_t bid = 0; bid < info.n_buckets; bid++) {
		zassert_ok(blob_db_inspect_bucket_get(bid, &bucket, NULL, NULL));
		fresh += bucket.formatted ? 0 : 1;
	}
	zassert_true(fresh > 0, "a formatted store has fresh buckets");

	zassert_equal(drain(), fresh);
	for (uint16_t bid = 0; bid < info.n_buckets; bid++) {
		zassert_ok(blob_db_inspect_bucket_get(bid, &bucket, NULL, NULL));
		zassert_true(bucket.formatted, "bucket %u left fresh", bid);
	}

	/* The headers are on flash: a remount finds nothing to do. */
	zassert_ok(blob_db_unmount());
	zassert_ok(blob_db_mount());
	zassert_equal(drain(), 0);
}

/* The lock: two threads binding their own ids, interleaved at every call,
 * with maintenance in between, lose nothing. */
#define WORKER_IDS   24
#define WORKER_STACK 16384

static K_THREAD_STACK_DEFINE(g_worker_stack, WORKER_STACK);
static struct k_thread g_worker;
static uint64_t g_worker_ids[WORKER_IDS];

static void fill(uint8_t *buf, size_t len, uint64_t id)
{
	for (size_t i = 0; i < len; i++) {
		buf[i] = (uint8_t)(id * 31 + i);
	}
}

static void bind_ids(uint64_t *ids, size_t n)
{
	uint8_t payload[48];

	for (size_t i = 0; i < n; i++) {
		ids[i] = blob_db_alloc_id();
		fill(payload, sizeof(payload), ids[i]);
		zassert_ok(blob_db_update(ids[i], payload, sizeof(payload)));
		k_yield();
		(void)blob_db_maintain(1, NULL);
		k_yield();
	}
}

static void worker(void *p1, void *p2, void *p3)
{
	ARG_UNUSED(p1);
	ARG_UNUSED(p2);
	ARG_UNUSED(p3);
	bind_ids(g_worker_ids, WORKER_IDS);
}

ZTEST(blob_db_maint, test_two_threads_interleave)
{
	uint64_t mine[WORKER_IDS];
	uint8_t want[48];
	uint8_t buf[48];
	size_t got;

	k_thread_create(&g_worker, g_worker_stack, WORKER_STACK, worker, NULL,
			NULL, NULL, k_thread_priority_get(k_current_get()), 0,
			K_NO_WAIT);
	bind_ids(mine, WORKER_IDS);
	zassert_ok(k_thread_join(&g_worker, K_SECONDS(30)));

	for (size_t i = 0; i < WORKER_IDS; i++) {
		const uint64_t ids[] = { mine[i], g_worker_ids[i] };

		for (size_t k = 0; k < ARRAY_SIZE(ids); k++) {
			fill(want, sizeof(want), ids[k]);
			zassert_ok(blob_db_get(ids[k], buf, sizeof(buf), &got));
			zassert_equal(got, sizeof(want));
			zassert_mem_equal(buf, want, sizeof(want));
		}
	}
	zassert_equal(blob_db_count(), 1 + 2 * WORKER_IDS);
}

#if defined(CONFIG_BLOB_DB_MAINT_WORK)
/* Generous: what a step takes on a target is measured there, not here —
 * native_sim runs every thread on a host stack. */
#define MAINT_Q_STACK 8192

static K_THREAD_STACK_DEFINE(g_maint_q_stack, MAINT_Q_STACK);
static struct k_work_q g_maint_q;
static bool g_maint_q_started;

static void maint_q_start(void)
{
	if (!g_maint_q_started) {
		k_work_queue_start(&g_maint_q, g_maint_q_stack, MAINT_Q_STACK,
				   K_LOWEST_APPLICATION_THREAD_PRIO, NULL);
		g_maint_q_started = true;
	}
}

/* Wait for the helper to leave nothing to do. */
static void wait_drained(void)
{
	for (int i = 0; i < 500; i++) {
		struct blob_db_maint_result res;

		zassert_ok(blob_db_maintain(0, &res));
		if (!res.more) {
			return;
		}
		k_msleep(10);
	}
	zassert_unreachable("the helper did not drain the work");
}
#endif

/* The helper drains on its own queue once started, and the work it leaves is
 * none. */
ZTEST(blob_db_maint, test_helper_drains_in_background)
{
	Z_TEST_SKIP_IFNDEF(CONFIG_BLOB_DB_MAINT_WORK);
	SKIP_UNLESS_WORK_IS_DEFERRED();
#if defined(CONFIG_BLOB_DB_MAINT_WORK)
	struct blob_db_maint_result res;

	maint_q_start();
	(void)make_work();
	zassert_ok(blob_db_maintain(0, &res));
	zassert_true(res.more, "make_work() must leave work for the helper");

	zassert_ok(blob_db_maint_start(&g_maint_q));
	wait_drained();
	blob_db_maint_stop();
#endif
}

/* Work that appears while the helper is started gets drained too: the
 * library kicks it, the caller does not. Stopped, it leaves work alone.
 *
 * The helper's queue runs at the lowest priority, so it gets the CPU only
 * when this thread sleeps: the work is still there right after it appears. */
ZTEST(blob_db_maint, test_helper_follows_new_work_until_stopped)
{
	Z_TEST_SKIP_IFNDEF(CONFIG_BLOB_DB_MAINT_WORK);
	SKIP_UNLESS_WORK_IS_DEFERRED();
#if defined(CONFIG_BLOB_DB_MAINT_WORK)
	struct blob_db_maint_result res;

	maint_q_start();
	zassert_ok(blob_db_maint_start(&g_maint_q));
	wait_drained();

	/* erase_all leaves fresh buckets on flash_area and released blocks
	 * on UBI, and kicks the helper either way. */
	zassert_ok(blob_db_erase_all());
	zassert_ok(blob_db_maintain(0, &res));
	zassert_true(res.more, "erase_all must leave work");
	wait_drained();

	/* So does a remount. */
	zassert_ok(blob_db_unmount());
	zassert_ok(blob_db_mount());
	wait_drained();

	blob_db_maint_stop();
	zassert_ok(blob_db_erase_all());
	k_msleep(100);
	zassert_ok(blob_db_maintain(0, &res));
	zassert_true(res.more, "a stopped helper must not run");
#endif
}
```

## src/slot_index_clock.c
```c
/*
 * Copyright (c) 2026
 * SPDX-License-Identifier: Apache-2.0
 *
 * The slot index as a cache (CONFIG_BLOB_DB_SLOT_INDEX_CLOCK).
 *
 * Correctness is the rest of the suite's job: in the slot_index.clock
 * scenarios every indexed answer is cross-checked against a walk
 * (CONFIG_BLOB_DB_SLOT_INDEX_VERIFY) while a 16-entry table evicts all the
 * time. This file checks the policy: ids looked up often stay indexed through
 * any amount of cold traffic -- ids written once, ids looked up once, deletes,
 * and compactions of the hot ids' own buckets -- so a hot lookup keeps
 * costing what a hit costs, not a walk.
 */

#include <errno.h>
#include <string.h>

#include <zephyr/ztest.h>

#include <app/lib/blob_db.h>
#include <app/lib/blob_db_iostats.h>
#include <app/lib/blob_db_inspect.h>

#define N_HOT   4
#define N_COLD  400
#define DEPTH   40   /* slots per hot bucket: a walk costs about this */

static void clock_before(void *fixture)
{
	ARG_UNUSED(fixture);
	if (!IS_ENABLED(CONFIG_BLOB_DB_SLOT_INDEX_CLOCK)) {
		ztest_test_skip();
	}
	blob_db_unmount();
	zassert_ok(blob_db_mount());
	zassert_ok(blob_db_format());
}

static void clock_after(void *fixture)
{
	ARG_UNUSED(fixture);
	blob_db_unmount();
}

ZTEST_SUITE(blob_db_sidx_clock, NULL, NULL, clock_before, clock_after, NULL);

static uint32_t reads_of_get(uint64_t id, uint8_t *buf, size_t sz)
{
	struct blob_db_iostats a, b;
	size_t len;

	blob_db_iostats_get(&a);
	zassert_ok(blob_db_get(id, buf, sz, &len), "get %llu", (unsigned long long)id);
	blob_db_iostats_get(&b);
	return b.reads - a.reads;
}

ZTEST(blob_db_sidx_clock, test_hot_ids_survive_cold_traffic)
{
	uint64_t hot[N_HOT];
	uint8_t v[32], buf[32];

	/* Hot ids, each rewritten until its bucket holds DEPTH slots, so a
	 * lookup that walks is clearly dearer than a hit. */
	for (int h = 0; h < N_HOT; h++) {
		hot[h] = blob_db_alloc_id();
		zassert_not_equal(hot[h], 0);
	}
	for (int r = 0; r < DEPTH; r++) {
		for (int h = 0; h < N_HOT; h++) {
			memset(v, r + h, sizeof(v));
			zassert_ok(blob_db_update(hot[h], v, sizeof(v)));
		}
	}

	/* What a walk of a hot bucket would cost: one header read per slot.
	 * A hit costs a header, the payload and its CRC; look each hot id up
	 * twice so the second is a hit whatever the first was. */
	struct blob_db_inspect_info ii;
	uint32_t hit = 0, walk = UINT32_MAX;

	zassert_ok(blob_db_inspect_info_get(&ii));
	for (int h = 0; h < N_HOT; h++) {
		struct blob_db_inspect_bucket bi;

		zassert_ok(blob_db_inspect_bucket_get((uint16_t)(hot[h] % ii.n_buckets),
						      &bi, NULL, NULL));
		walk = MIN(walk, (uint32_t)bi.objects + bi.superseded + bi.tombstones);
		(void)reads_of_get(hot[h], buf, sizeof(buf));
		hit = MAX(hit, reads_of_get(hot[h], buf, sizeof(buf)));
	}
	if (!IS_ENABLED(CONFIG_BLOB_DB_SLOT_INDEX_VERIFY)) {
		zassert_true(walk > 4 * hit, "walk %u reads, hit %u: test not sensitive",
			     walk, hit);
	}

	/* Cold traffic, many times the table: each cold id is written, looked
	 * up once (which learns it, and so must evict), and half are deleted.
	 * The hot ids are looked up between every cold step, and rewritten now
	 * and then, so their buckets also compact. */
	uint32_t worst = 0;

	for (int c = 0; c < N_COLD; c++) {
		uint64_t id = blob_db_alloc_id();

		zassert_not_equal(id, 0);
		memset(v, 0xc0 ^ c, sizeof(v));
		zassert_ok(blob_db_update(id, v, sizeof(v)));
		zassert_ok(blob_db_get(id, buf, sizeof(buf), NULL));
		if (c % 2) {
			zassert_ok(blob_db_delete(id));
		}
		if (c % 7 == 0) {
			memset(v, c, sizeof(v));
			zassert_ok(blob_db_update(hot[c % N_HOT], v, sizeof(v)));
			/* A rewrite refreshes the entry; the next get is a hit. */
		}
		for (int h = 0; h < N_HOT; h++) {
			uint32_t r = reads_of_get(hot[h], buf, sizeof(buf));

			if (c >= N_HOT) {   /* past the warm-up */
				worst = MAX(worst, r);
			}
		}
	}

	if (!IS_ENABLED(CONFIG_BLOB_DB_SLOT_INDEX_VERIFY)) {
		zassert_true(worst <= hit, "a hot lookup cost %u reads (hit %u, walk %u): "
			     "a hot id was evicted", worst, hit, walk);
	}

	/* And the values are right. */
	for (int h = 0; h < N_HOT; h++) {
		size_t len;

		zassert_ok(blob_db_get(hot[h], buf, sizeof(buf), &len));
		zassert_equal(len, sizeof(v));
	}
}
```
